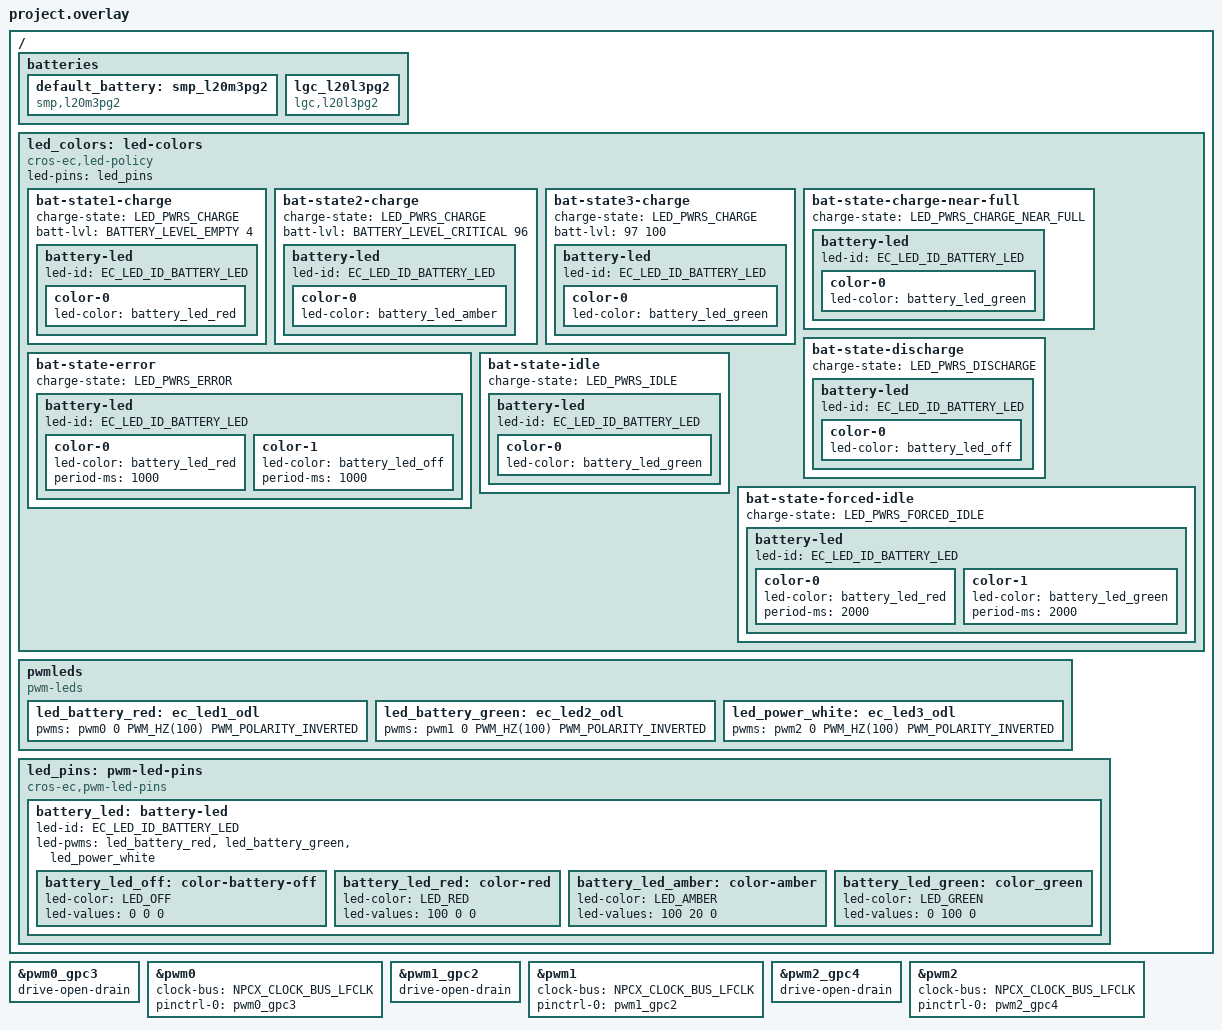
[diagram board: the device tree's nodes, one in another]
/* Copyright 2022 The ChromiumOS Authors
 * Use of this source code is governed by a BSD-style license that can be
 * found in the LICENSE file.
 */

/* Corsola program common DTS includes */

#include "../common.dtsi"
#include "../power_signal.dtsi"
#include "../usba.dtsi"
#include "../npcx_adc.dtsi"
#include "../npcx_host_interface.dtsi"
#include "../npcx_i2c.dtsi"
#include "../npcx_interrupts.dtsi"
#include "../npcx_gpio.dtsi"
#include "../npcx_keyboard.dtsi"
#include "../npcx_motionsense.dtsi"
#include "../npcx_usbc.dtsi"
#include "../npcx_default_gpio_pinctrl.dtsi"
#include <dt-bindings/battery.h>

/* board override */
/ {
	batteries {
		default_battery: smp_l20m3pg2 {
			compatible = "smp,l20m3pg2", "battery-smart";
		};
		lgc_l20l3pg2 {
			compatible = "lgc,l20l3pg2", "battery-smart";
		};
	};

	led_colors: led-colors {
		compatible = "cros-ec,led-policy";
		led-pins = <&led_pins>;

		/* kingler LED bat charge */
		bat-state1-charge {
			charge-state = "LED_PWRS_CHARGE";
			/* Battery display percent range (>= 0, <= 4%) */
			batt-lvl = <BATTERY_LEVEL_EMPTY 4>;

			battery-led {
				led-id = "EC_LED_ID_BATTERY_LED";
				color-0 {
					led-color = <&battery_led_red>;
				};
			};
		};

		bat-state2-charge {
			charge-state = "LED_PWRS_CHARGE";
			/* Battery display percent range (>= 5, <= 96%) */
			batt-lvl = <BATTERY_LEVEL_CRITICAL 96>;

			battery-led {
				led-id = "EC_LED_ID_BATTERY_LED";
				color-0 {
					led-color = <&battery_led_amber>;
				};
			};
		};

		bat-state3-charge {
			charge-state = "LED_PWRS_CHARGE";
			/* Battery display percent range (>= 97, <= 100) */
			batt-lvl = <97 100>;

			battery-led {
				led-id = "EC_LED_ID_BATTERY_LED";
				color-0 {
					led-color = <&battery_led_green>;
				};
			};
		};

		/* kingler LED bat charge near full */
		bat-state-charge-near-full {
			charge-state = "LED_PWRS_CHARGE_NEAR_FULL";

			battery-led {
				led-id = "EC_LED_ID_BATTERY_LED";
				color-0 {
					led-color = <&battery_led_green>;
				};
			};
		};

		/* kingler LED bat discharge */
		bat-state-discharge {
			charge-state = "LED_PWRS_DISCHARGE";

			battery-led {
				led-id = "EC_LED_ID_BATTERY_LED";
				color-0 {
					led-color = <&battery_led_off>;
				};
			};
		};

		/* kingler LED bat error */
		bat-state-error {
			charge-state = "LED_PWRS_ERROR";

			battery-led {
				led-id = "EC_LED_ID_BATTERY_LED";
				color-0 {
					led-color = <&battery_led_red>;
					period-ms = <1000>;
				};
				color-1 {
					led-color = <&battery_led_off>;
					period-ms = <1000>;
				};
			};
		};

		/* kingler LED bat idle */
		bat-state-idle {
			charge-state = "LED_PWRS_IDLE";

			battery-led {
				led-id = "EC_LED_ID_BATTERY_LED";
				color-0 {
					led-color = <&battery_led_green>;
				};
			};
		};

		/* kingler LED bat forced idle */
		bat-state-forced-idle {
			charge-state = "LED_PWRS_FORCED_IDLE";

			battery-led {
				led-id = "EC_LED_ID_BATTERY_LED";
				color-0 {
					led-color = <&battery_led_red>;
					period-ms = <2000>;
				};
				color-1 {
					led-color = <&battery_led_green>;
					period-ms = <2000>;
				};
			};
		};
	};
	pwmleds {
		compatible = "pwm-leds";
		led_battery_red: ec_led1_odl {
			pwms = <&pwm0 0 PWM_HZ(100) PWM_POLARITY_INVERTED>;
		};
		led_battery_green: ec_led2_odl {
			pwms = <&pwm1 0 PWM_HZ(100) PWM_POLARITY_INVERTED>;
		};
		led_power_white: ec_led3_odl {
			pwms = <&pwm2 0 PWM_HZ(100) PWM_POLARITY_INVERTED>;
		};
	};

	led_pins: pwm-led-pins {
		compatible = "cros-ec,pwm-led-pins";

		battery_led: battery-led {
			led-id = "EC_LED_ID_BATTERY_LED";
			led-pwms = <&led_battery_red &led_battery_green &led_power_white>;

			battery_led_off: color-battery-off {
				led-color = "LED_OFF";
				led-values = <0 0 0>;
			};

			battery_led_red: color-red {
				led-color = "LED_RED";
				led-values = <100 0 0>;
			};

			battery_led_amber: color-amber {
				led-color = "LED_AMBER";
				led-values = <100 20 0>;
			};

			battery_led_green: color_green {
				led-color = "LED_GREEN";
				led-values = <0 100 0>;
			};
		};

	};
};

/* Red LED */
&pwm0_gpc3 {
	drive-open-drain;
};

&pwm0 {
	status = "okay";
	clock-bus = "NPCX_CLOCK_BUS_LFCLK";
	pinctrl-0 = <&pwm0_gpc3>;
	pinctrl-names = "default";
};

/* Green LED */
&pwm1_gpc2 {
	drive-open-drain;
};

&pwm1 {
	status = "okay";
	clock-bus = "NPCX_CLOCK_BUS_LFCLK";
	pinctrl-0 = <&pwm1_gpc2>;
	pinctrl-names = "default";
};

/* Blue LED */
&pwm2_gpc4 {
	drive-open-drain;
};

&pwm2 {
	status = "okay";
	clock-bus = "NPCX_CLOCK_BUS_LFCLK";
	pinctrl-0 = <&pwm2_gpc4>;
	pinctrl-names = "default";
};
